# ionuc505 register map
Registers from a debugger description file.
Registers are 32-bit, access not given, no defined reset value unless marked. A register's access mark holds for its fields unless they carry their own. Addresses are absolute; registers are grouped by the start of their names; lines under a group give offsets from that group; [hi:lo] are bit positions; {n}, {i} and the like mark numbered series; 'fields as' and 'values as' point back to an identical list; <NAME> marks a mode.

## GCR
0x40000000 GCR_SYS_PDID
  [23:0] PDID
0x40000004 GCR_SYS_BOOTSET
  [3:0] BOOTSET
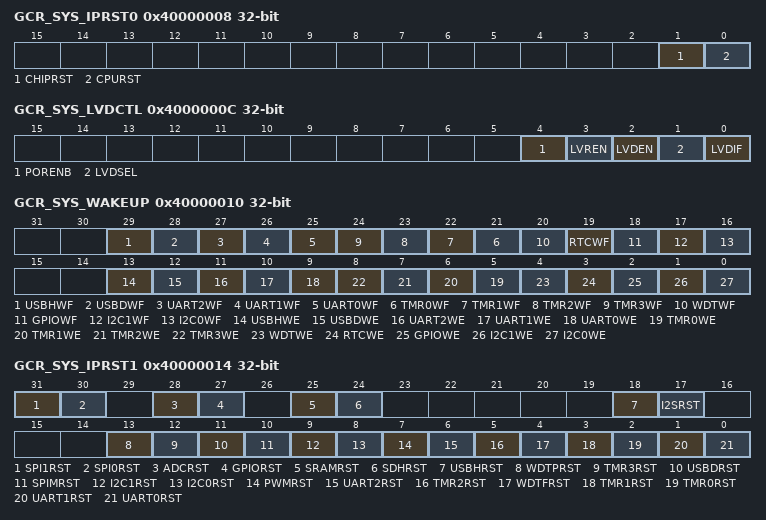
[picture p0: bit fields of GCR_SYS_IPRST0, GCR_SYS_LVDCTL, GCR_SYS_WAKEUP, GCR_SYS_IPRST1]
0x40000008 GCR_SYS_IPRST0
  [1] CHIPRST, [0] CPURST
0x4000000C GCR_SYS_LVDCTL
  [4] PORENB, [3] LVREN, [2] LVDEN, [1] LVDSEL, [0] LVDIF
0x40000010 GCR_SYS_WAKEUP
  [29] USBHWF, [28] USBDWF, [27] UART2WF, [26] UART1WF, [25] UART0WF, [n+21] TMR{n}WF (n=0..3), [20] WDTWF, [19] RTCWF, [18] GPIOWF, [17] I2C1WF, [16] I2C0WF, [13] USBHWE, [12] USBDWE, [11] UART2WE, [10] UART1WE, [9] UART0WE, [n+5] TMR{n}WE (n=0..3), [4] WDTWE, [3] RTCWE, [2] GPIOWE, [1] I2C1WE, [0] I2C0WE
0x40000014 GCR_SYS_IPRST1
  [31] SPI1RST, [30] SPI0RST, [28] ADCRST, [27] GPIORST, [25] SRAMRST, [24] SDHRST, [18] USBHRST, [17] I2SRST, [13] WDTPRST, [12] TMR3RST, [11] USBDRST, [10] SPIMRST, [9] I2C1RST, [8] I2C0RST, [7] PWMRST, [6] UART2RST, [5] TMR2RST, [4] WDTFRST, [3] TMR1RST, [2] TMR0RST, [1] UART1RST, [0] UART0RST
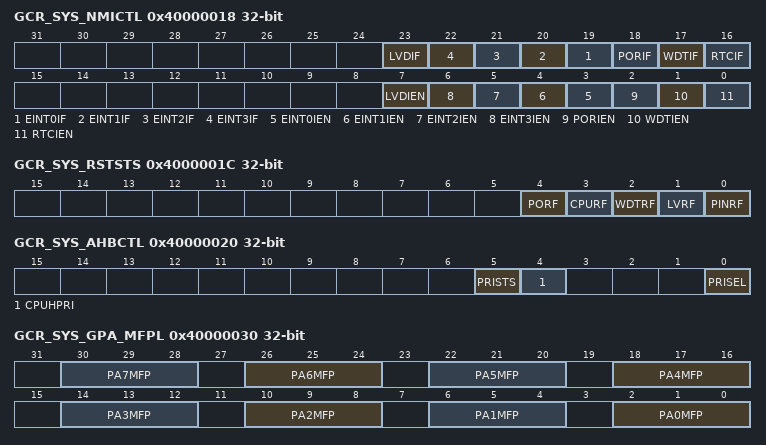
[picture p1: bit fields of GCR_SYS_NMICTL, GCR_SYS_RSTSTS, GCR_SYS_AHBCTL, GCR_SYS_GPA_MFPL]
0x40000018 GCR_SYS_NMICTL
  [23] LVDIF, [n+19] EINT{n}IF (n=0..3), [18] PORIF, [17] WDTIF, [16] RTCIF, [7] LVDIEN, [n+3] EINT{n}IEN (n=0..3), [2] PORIEN, [1] WDTIEN, [0] RTCIEN
0x4000001C GCR_SYS_RSTSTS
  [4] PORF, [3] CPURF, [2] WDTRF, [1] LVRF, [0] PINRF
0x40000020 GCR_SYS_AHBCTL
  [5] PRISTS, [4] CPUHPRI, [0] PRISEL
0x40000030 GCR_SYS_GPA_MFPL
  [4n+2:4n] PA{n}MFP (n=0..7)
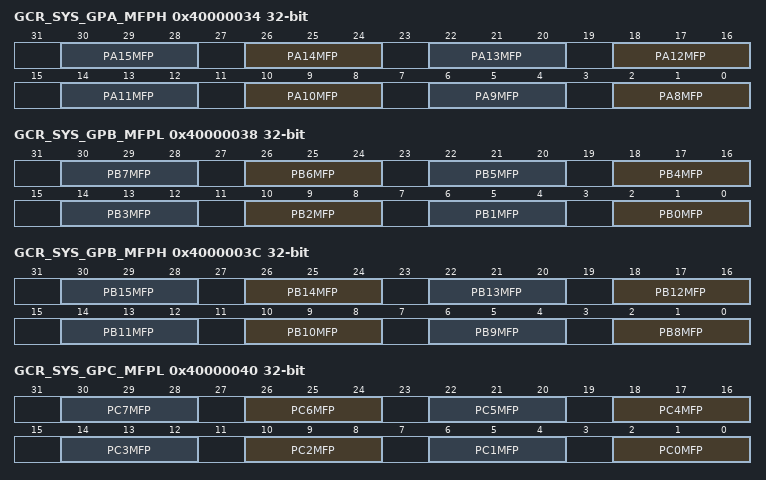
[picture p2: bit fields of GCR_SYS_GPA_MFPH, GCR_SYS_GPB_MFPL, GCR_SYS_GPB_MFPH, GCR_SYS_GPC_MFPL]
0x40000034 GCR_SYS_GPA_MFPH
  [4n-30:4n-32] PA{n}MFP (n=8..15)
0x40000038 GCR_SYS_GPB_MFPL
  [4n+2:4n] PB{n}MFP (n=0..7)
0x4000003C GCR_SYS_GPB_MFPH
  [4n-30:4n-32] PB{n}MFP (n=8..15)
0x40000040 GCR_SYS_GPC_MFPL
  [4n+2:4n] PC{n}MFP (n=0..7)
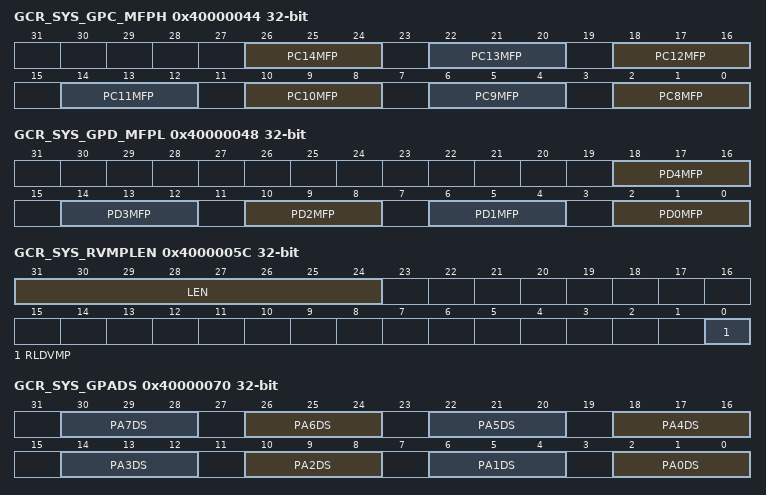
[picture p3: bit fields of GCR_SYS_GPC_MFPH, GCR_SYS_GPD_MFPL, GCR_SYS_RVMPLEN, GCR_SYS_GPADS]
0x40000044 GCR_SYS_GPC_MFPH
  [4n-30:4n-32] PC{n}MFP (n=8..14)
0x40000048 GCR_SYS_GPD_MFPL
  [4n+2:4n] PD{n}MFP (n=0..4)
0x40000050 GCR_SYS_LVMPADDR
0x40000054 GCR_SYS_LVMPLEN
  [7:0] LEN
0x40000058 GCR_SYS_RVMPADDR
0x4000005C GCR_SYS_RVMPLEN
  [31:24] LEN, [0] RLDVMP
0x4000006C GCR_SYS_EPADPUEN
  [4:0] EPADPUEN
0x40000070 GCR_SYS_GPADS
  [4n+2:4n] PA{n}DS (n=0..7)
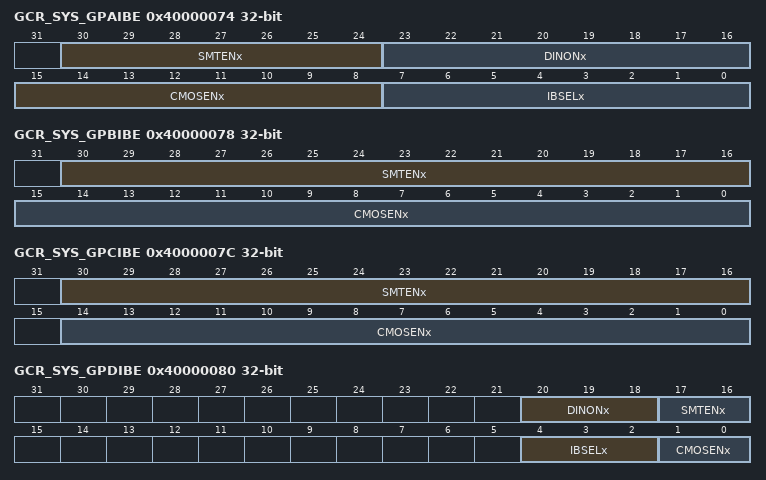
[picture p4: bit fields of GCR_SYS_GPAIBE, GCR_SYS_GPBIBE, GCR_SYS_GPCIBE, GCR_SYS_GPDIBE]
0x40000074 GCR_SYS_GPAIBE
  [30:24] SMTENx, [23:16] DINONx, [15:8] CMOSENx, [7:0] IBSELx
0x40000078 GCR_SYS_GPBIBE
  [30:16] SMTENx, [15:0] CMOSENx
0x4000007C GCR_SYS_GPCIBE
  [30:16] SMTENx, [14:0] CMOSENx
0x40000080 GCR_SYS_GPDIBE
  [20:18] DINONx, [17:16] SMTENx, [4:2] IBSELx, [1:0] CMOSENx
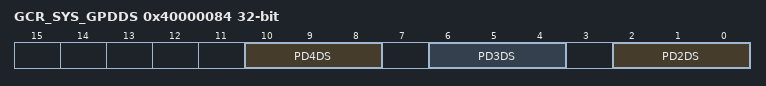
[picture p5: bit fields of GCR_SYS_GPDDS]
0x40000084 GCR_SYS_GPDDS
  [10:8] PD4DS, [6:4] PD3DS, [2:0] PD2DS
0x40000100 GCR_SYS_RSTDBCNT
  [15:0] RSTDBCNT
0x40000104 GCR_SYS_RSTDBEN
  [0] RSTDBEN

## SCS
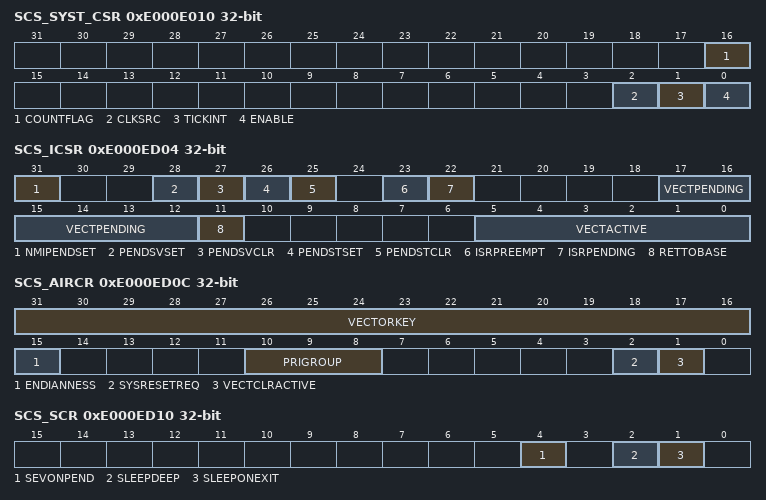
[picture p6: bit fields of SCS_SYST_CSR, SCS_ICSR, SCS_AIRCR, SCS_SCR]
0xE000E010 SCS_SYST_CSR
  [16] COUNTFLAG, [2] CLKSRC, [1] TICKINT, [0] ENABLE
0xE000E014 SCS_SYST_RVR
  [23:0] RELOAD
0xE000E018 SCS_SYST_CVR
  [23:0] CURRENT
0xE000E100 SCS_NVIC_ISER0
0xE000E180 SCS_NVIC_ICER0
0xE000E200 SCS_NVIC_ISPR0
0xE000E280 SCS_NVIC_ICPR0
0xE000E300 SCS_NVIC_IABR0
0xE000ED04 SCS_ICSR
  [31] NMIPENDSET, [28] PENDSVSET, [27] PENDSVCLR, [26] PENDSTSET, [25] PENDSTCLR, [23] ISRPREEMPT, [22] ISRPENDING, [17:12] VECTPENDING, [11] RETTOBASE, [5:0] VECTACTIVE
0xE000ED0C SCS_AIRCR
  [31:16] VECTORKEY, [15] ENDIANNESS, [10:8] PRIGROUP, [2] SYSRESETREQ, [1] VECTCLRACTIVE
0xE000ED10 SCS_SCR
  [4] SEVONPEND, [2] SLEEPDEEP, [1] SLEEPONEXIT
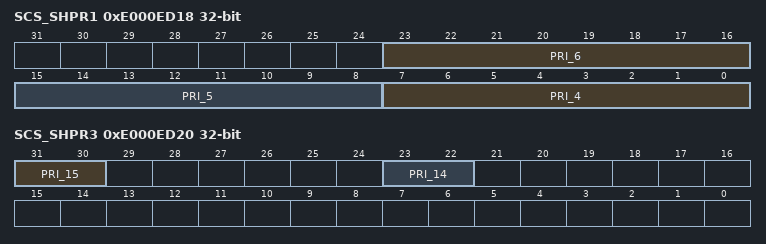
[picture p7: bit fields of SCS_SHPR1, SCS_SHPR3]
0xE000ED18 SCS_SHPR1
  [23:16] PRI_6, [15:8] PRI_5, [7:0] PRI_4
0xE000ED1C SCS_SHPR2
  [31:30] PRI_11
0xE000ED20 SCS_SHPR3
  [31:30] PRI_15, [23:22] PRI_14
0xE000EF00 SCS_NVIC_STIR
  [8:0] INTID
